# APM32F091 register map
File version: 1.0
Registers are 32-bit, read-write, reset 0x0 unless marked. A register's access mark holds for its fields unless they carry their own. Offsets are from the block's base; [hi:lo] are bit positions; {n}, {i} and the like mark numbered series.

## COMP — Comparator
Base 0x4001001C
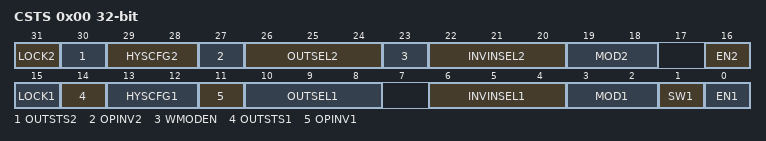
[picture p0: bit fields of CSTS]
0x00 CSTS access per field — control and status register
  [31] LOCK2 rw — Comparator 2 lock
  [30] OUTSTS2 ro — Comparator 2 output
  [29:28] HYSCFG2 rw — Comparator 2 hysteresis
  [27] OPINV2 rw — Comparator 2 output polarity
  [26:24] OUTSEL2 rw — Comparator 2 output selection
  [23] WMODEN rw — Window mode enable
  [22:20] INVINSEL2 rw — Comparator 2 inverting input selection
  [19:18] MOD2 rw — Comparator 2 mode
  [16] EN2 rw — Comparator 2 enable
  [15] LOCK1 rw — Comparator 1 lock
  [14] OUTSTS1 ro — Comparator 1 output
  [13:12] HYSCFG1 rw — Comparator 1 hysteresis
  [11] OPINV1 rw — Comparator 1 output polarity
  [10:8] OUTSEL1 rw — Comparator 1 output selection
  [6:4] INVINSEL1 rw — Comparator 1 inverting input selection
  [3:2] MOD1 rw — Comparator 1 mode
  [1] SW1 rw — COMP1SW
  [0] EN1 rw — Comparator 1 enable

## FMC — Flash
Base 0x40022000
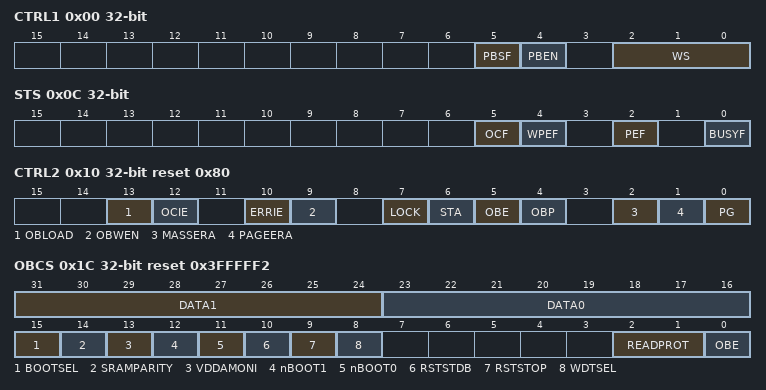
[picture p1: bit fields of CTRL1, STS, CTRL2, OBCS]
0x00 CTRL1 access per field — Flash access control register
  [5] PBSF ro
  [4] PBEN rw
  [2:0] WS rw — LATENCY
0x04 KEY wo — Flash key register
  [31:0] KEY — Flash Key
0x08 OBKEY wo — Flash option key register
  [31:0] OBKEY — Option byte key
0x0C STS access per field — Flash status register
  [5] OCF rw — End of operation
  [4] WPEF rw — Write protection error
  [2] PEF rw — Programming error
  [0] BUSYF ro — Busy
0x10 CTRL2 reset 0x80 — Flash control register
  [13] OBLOAD — Force option byte loading
  [12] OCIE — End of operation interrupt enable
  [10] ERRIE — Error interrupt enable
  [9] OBWEN — Option bytes write enable
  [7] LOCK
  [6] STA — Start
  [5] OBE — Option byte erase
  [4] OBP — Option byte programming
  [2] MASSERA — Mass erase
  [1] PAGEERA — Page erase
  [0] PG — Programming
0x14 ADDR wo — Flash address register
  [31:0] ADDR — Flash address
0x1C OBCS ro reset 0x3FFFFF2 — Option byte register
  [31:24] DATA1
  [23:16] DATA0
  [15] BOOTSEL — BOOT0 Signal Select
  [14] SRAMPARITY — RPC
  [13] VDDAMONI — VDDAMON
  [12] nBOOT1 — BOT1
  [11] nBOOT0 — BOT0
  [10] RSTSTDB — RSTSTDBY
  [9] RSTSTOP
  [8] WDTSEL
  [2:1] READPROT — Level x protection status
  [0] OBE — Option byte error
0x20 WRTPROT ro reset 0xFFFFFFFF — Write protection register
  [31:0] WRTPROT — Write protect

## DBG — Debug support
Base 0x40015800
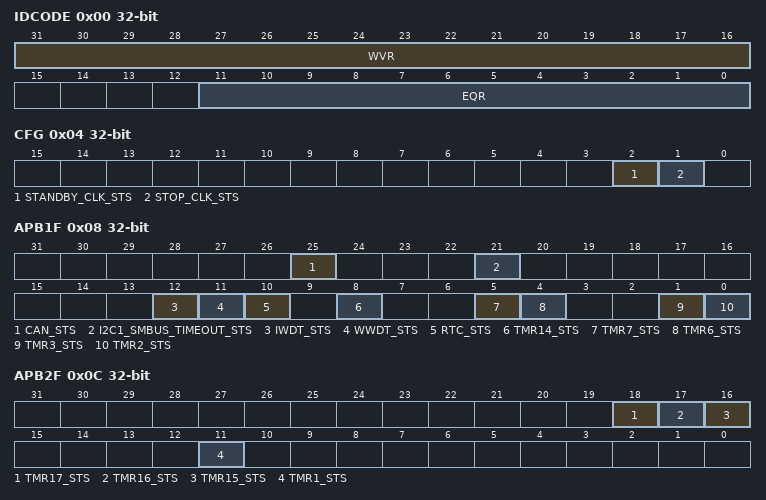
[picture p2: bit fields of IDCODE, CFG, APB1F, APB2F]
0x00 IDCODE ro — MCU Device ID Code Register
  [31:16] WVR — Revision Identifier
  [11:0] EQR — Device Identifier
0x04 CFG — Debug MCU Configuration Register
  [2] STANDBY_CLK_STS — Debug Standby Mode
  [1] STOP_CLK_STS — Debug Stop Mode
0x08 APB1F — APB Low Freeze Register
  [25] CAN_STS — Debug CAN stopped when Core is halted
  [21] I2C1_SMBUS_TIMEOUT_STS — I2C1 SMBUS timeout mode stopped when Core is halted
  [12] IWDT_STS — Debug Independent Wachdog stopped when Core is halted
  [11] WWDT_STS — Debug Window Wachdog stopped when Core is halted
  [10] RTC_STS — Debug RTC stopped when Core is halted
  [8] TMR14_STS — Debug Timer 14 stopped when Core is halted
  [5] TMR7_STS — Debug Timer 7 stopped when Core is halted
  [4] TMR6_STS — Debug Timer 6 stopped when Core is halted
  [1] TMR3_STS — Debug Timer 3 stopped when Core is halted
  [0] TMR2_STS — Debug Timer 2 stopped when Core is halted
0x0C APB2F — APB High Freeze Register
  [18] TMR17_STS — Debug Timer 17 stopped when Core is halted
  [17] TMR16_STS — Debug Timer 16 stopped when Core is halted
  [16] TMR15_STS — Debug Timer 15 stopped when Core is halted
  [11] TMR1_STS — Debug Timer 1 stopped when Core is halted

## NVIC — Nested Vectored Interrupt Controller
Base 0xE000E100
0x00 ISER — Interrupt Set Enable Register
  [31:0] SETENA
0x80 ICER — Interrupt Clear Enable Register
  [31:0] CLRENA
0x100 ISPR — Interrupt Set-Pending Register
  [31:0] SETPEND
0x180 ICPR — Interrupt Clear-Pending Register
  [31:0] CLRPEND
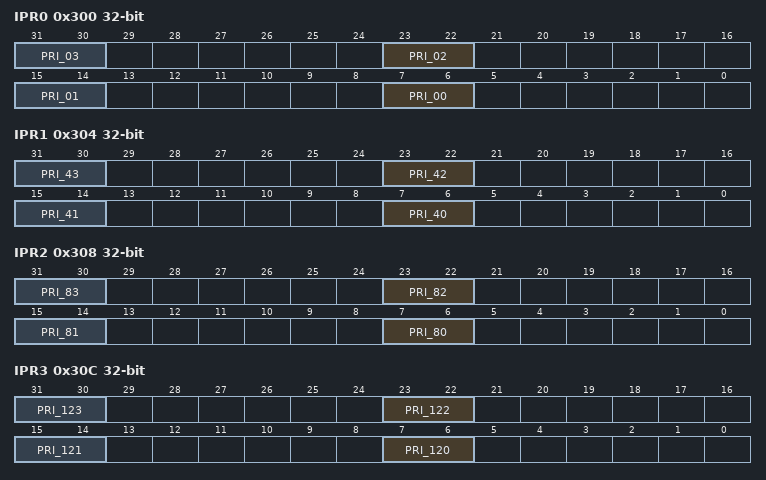
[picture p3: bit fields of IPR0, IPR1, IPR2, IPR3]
0x300 IPR0 — Interrupt Priority Register 0
  [8n+7:8n+6] PRI_{n:02} (n=0..3)
0x304 IPR1 — Interrupt Priority Register 1
  [8n-313:8n-314] PRI_{n} (n=40..43)
0x308 IPR2 — Interrupt Priority Register 2
  [8n-633:8n-634] PRI_{n} (n=80..83)
0x30C IPR3 — Interrupt Priority Register 3
  [8n-953:8n-954] PRI_{n} (n=120..123)
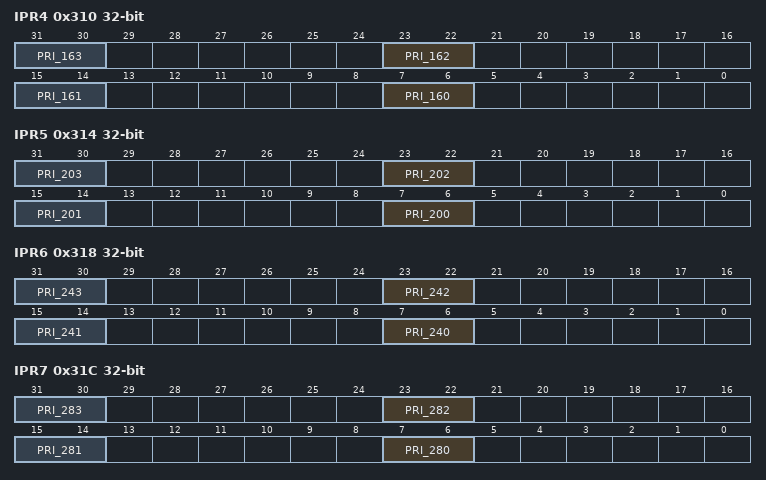
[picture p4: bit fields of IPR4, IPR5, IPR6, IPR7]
0x310 IPR4 — Interrupt Priority Register 4
  [8n-1273:8n-1274] PRI_{n} (n=160..163)
0x314 IPR5 — Interrupt Priority Register 5
  [8n-1593:8n-1594] PRI_{n} (n=200..203)
0x318 IPR6 — Interrupt Priority Register 6
  [8n-1913:8n-1914] PRI_{n} (n=240..243)
0x31C IPR7 — Interrupt Priority Register 7
  [8n-2233:8n-2234] PRI_{n} (n=280..283)
